# ESP32-P4 register map
Vendor: ESPRESSIF SYSTEMS (SHANGHAI) CO., LTD.; Series: ESP32 P-Series; File version: 3
CPU: RV32IMAFC r0p0, little endian, no MPU, FPU, 0 interrupt priority bits
Address unit: 32 bits
Registers are 32-bit, read-write, reset 0x0 unless marked. A register's access mark holds for its fields unless they carry their own. Offsets are from the block's base; [hi:lo] are bit positions; {n}, {i} and the like mark numbered series; 'fields as' and 'values as' point back to an identical list.

## MEMSPI2 — Memory SPI 2
Base 0x5008E000
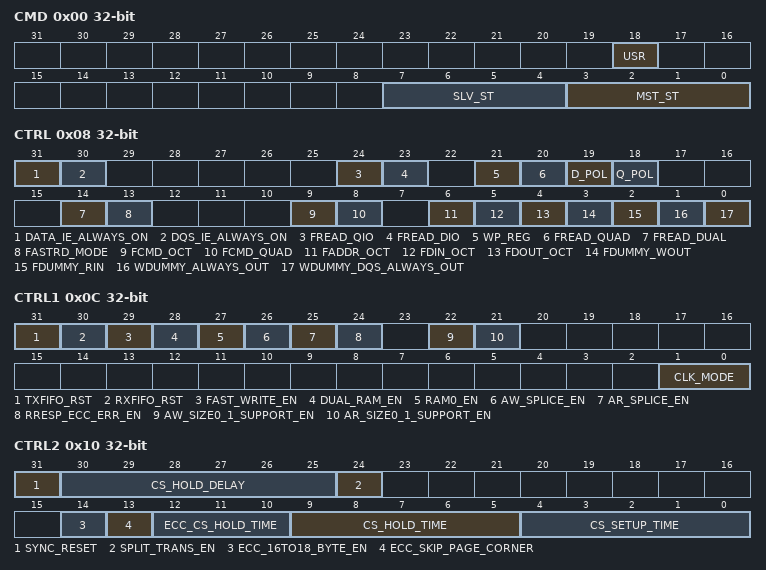
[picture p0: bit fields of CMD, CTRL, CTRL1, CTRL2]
0x00 CMD access per field
  [18] USR rw, [7:4] SLV_ST ro, [3:0] MST_ST ro
0x08 CTRL
  [31] DATA_IE_ALWAYS_ON, [30] DQS_IE_ALWAYS_ON, [24] FREAD_QIO, [23] FREAD_DIO, [21] WP_REG, [20] FREAD_QUAD, [19] D_POL, [18] Q_POL, [14] FREAD_DUAL, [13] FASTRD_MODE, [9] FCMD_OCT, [8] FCMD_QUAD, [6] FADDR_OCT, [5] FDIN_OCT, [4] FDOUT_OCT, [3] FDUMMY_WOUT, [2] FDUMMY_RIN, [1] WDUMMY_ALWAYS_OUT, [0] WDUMMY_DQS_ALWAYS_OUT
0x0C CTRL1 access per field
  [31] TXFIFO_RST wo, [30] RXFIFO_RST wo, [29] FAST_WRITE_EN rw, [28] DUAL_RAM_EN rw, [27] RAM0_EN rw, [26] AW_SPLICE_EN rw, [25] AR_SPLICE_EN rw, [24] RRESP_ECC_ERR_EN rw, [22] AW_SIZE0_1_SUPPORT_EN rw, [21] AR_SIZE0_1_SUPPORT_EN rw, [1:0] CLK_MODE rw
0x10 CTRL2 access per field
  [31] SYNC_RESET wo, [30:25] CS_HOLD_DELAY rw, [24] SPLIT_TRANS_EN rw, [14] ECC_16TO18_BYTE_EN rw, [13] ECC_SKIP_PAGE_CORNER rw, [12:10] ECC_CS_HOLD_TIME rw, [9:5] CS_HOLD_TIME rw, [4:0] CS_SETUP_TIME rw
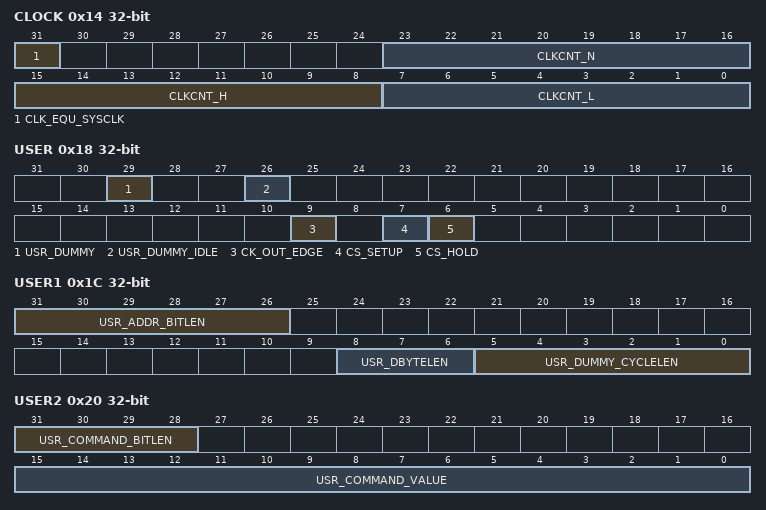
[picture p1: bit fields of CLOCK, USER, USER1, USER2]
0x14 CLOCK
  [31] CLK_EQU_SYSCLK, [23:16] CLKCNT_N, [15:8] CLKCNT_H, [7:0] CLKCNT_L
0x18 USER
  [29] USR_DUMMY, [26] USR_DUMMY_IDLE, [9] CK_OUT_EDGE, [7] CS_SETUP, [6] CS_HOLD
0x1C USER1
  [31:26] USR_ADDR_BITLEN, [8:6] USR_DBYTELEN, [5:0] USR_DUMMY_CYCLELEN
0x20 USER2
  [31:28] USR_COMMAND_BITLEN, [15:0] USR_COMMAND_VALUE
0x2C RD_STATUS
  [23:16] WB_MODE
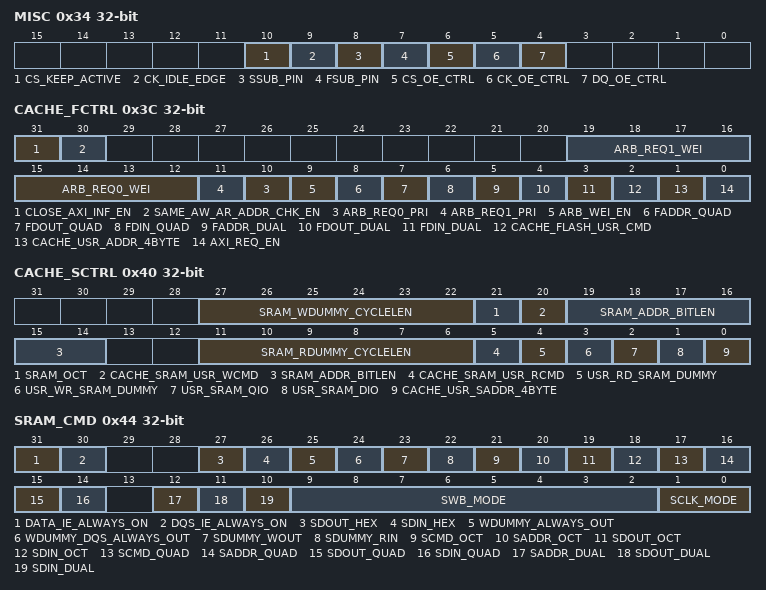
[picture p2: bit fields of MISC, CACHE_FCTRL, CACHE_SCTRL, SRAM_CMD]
0x34 MISC
  [10] CS_KEEP_ACTIVE, [9] CK_IDLE_EDGE, [8] SSUB_PIN, [7] FSUB_PIN, [6] CS_OE_CTRL, [5] CK_OE_CTRL, [4] DQ_OE_CTRL
0x3C CACHE_FCTRL
  [31] CLOSE_AXI_INF_EN, [30] SAME_AW_AR_ADDR_CHK_EN, [4n+15:4n+12] ARB_REQ{n}_WEI (n=0..1), [n+10] ARB_REQ{n}_PRI (n=0..1), [9] ARB_WEI_EN, [8] FADDR_QUAD, [7] FDOUT_QUAD, [6] FDIN_QUAD, [5] FADDR_DUAL, [4] FDOUT_DUAL, [3] FDIN_DUAL, [2] CACHE_FLASH_USR_CMD, [1] CACHE_USR_ADDR_4BYTE, [0] AXI_REQ_EN
0x40 CACHE_SCTRL
  [27:22] SRAM_WDUMMY_CYCLELEN, [21] SRAM_OCT, [20] CACHE_SRAM_USR_WCMD, [19:14] SRAM_ADDR_BITLEN, [11:6] SRAM_RDUMMY_CYCLELEN, [5] CACHE_SRAM_USR_RCMD, [4] USR_RD_SRAM_DUMMY, [3] USR_WR_SRAM_DUMMY, [2] USR_SRAM_QIO, [1] USR_SRAM_DIO, [0] CACHE_USR_SADDR_4BYTE
0x44 SRAM_CMD
  [31] DATA_IE_ALWAYS_ON, [30] DQS_IE_ALWAYS_ON, [27] SDOUT_HEX, [26] SDIN_HEX, [25] WDUMMY_ALWAYS_OUT, [24] WDUMMY_DQS_ALWAYS_OUT, [23] SDUMMY_WOUT, [22] SDUMMY_RIN, [21] SCMD_OCT, [20] SADDR_OCT, [19] SDOUT_OCT, [18] SDIN_OCT, [17] SCMD_QUAD, [16] SADDR_QUAD, [15] SDOUT_QUAD, [14] SDIN_QUAD, [12] SADDR_DUAL, [11] SDOUT_DUAL, [10] SDIN_DUAL, [9:2] SWB_MODE, [1:0] SCLK_MODE
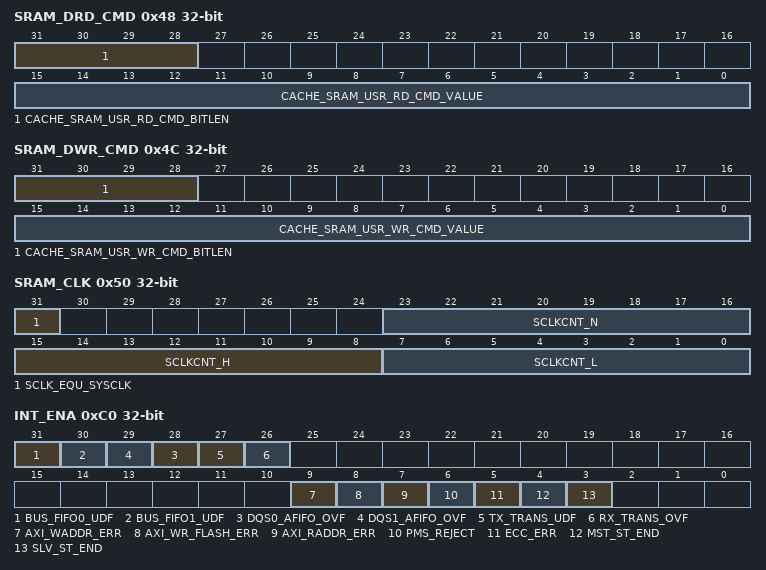
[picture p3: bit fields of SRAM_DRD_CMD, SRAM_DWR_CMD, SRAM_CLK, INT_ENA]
0x48 SRAM_DRD_CMD
  [31:28] CACHE_SRAM_USR_RD_CMD_BITLEN, [15:0] CACHE_SRAM_USR_RD_CMD_VALUE
0x4C SRAM_DWR_CMD
  [31:28] CACHE_SRAM_USR_WR_CMD_BITLEN, [15:0] CACHE_SRAM_USR_WR_CMD_VALUE
0x50 SRAM_CLK
  [31] SCLK_EQU_SYSCLK, [23:16] SCLKCNT_N, [15:8] SCLKCNT_H, [7:0] SCLKCNT_L
0x54 FSM
  [18:7] LOCK_DELAY_TIME
0xC0 INT_ENA
  [31] BUS_FIFO0_UDF, [30] BUS_FIFO1_UDF, [n+28] DQS{n}_AFIFO_OVF (n=0..1), [27] TX_TRANS_UDF, [26] RX_TRANS_OVF, [9] AXI_WADDR_ERR, [8] AXI_WR_FLASH_ERR, [7] AXI_RADDR_ERR, [6] PMS_REJECT, [5] ECC_ERR, [4] MST_ST_END, [3] SLV_ST_END
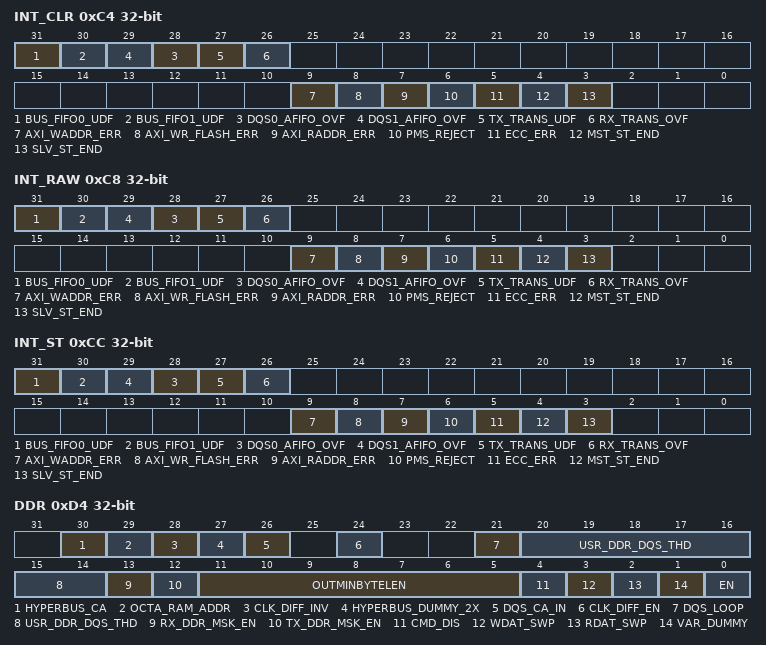
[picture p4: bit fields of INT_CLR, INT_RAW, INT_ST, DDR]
0xC4 INT_CLR wo
  [31] BUS_FIFO0_UDF write-1-clears, [30] BUS_FIFO1_UDF write-1-clears, [n+28] DQS{n}_AFIFO_OVF (n=0..1) write-1-clears, [27] TX_TRANS_UDF write-1-clears, [26] RX_TRANS_OVF write-1-clears, [9] AXI_WADDR_ERR write-1-clears, [8] AXI_WR_FLASH_ERR write-1-clears, [7] AXI_RADDR_ERR write-1-clears, [6] PMS_REJECT write-1-clears, [5] ECC_ERR write-1-clears, [4] MST_ST_END write-1-clears, [3] SLV_ST_END write-1-clears
0xC8 INT_RAW
  fields as INT_ENA
0xCC INT_ST ro
  fields as INT_ENA
0xD4 DDR
  [30] HYPERBUS_CA, [29] OCTA_RAM_ADDR, [28] CLK_DIFF_INV, [27] HYPERBUS_DUMMY_2X, [26] DQS_CA_IN, [24] CLK_DIFF_EN, [21] DQS_LOOP, [20:14] USR_DDR_DQS_THD, [13] RX_DDR_MSK_EN, [12] TX_DDR_MSK_EN, [11:5] OUTMINBYTELEN, [4] CMD_DIS, [3] WDAT_SWP, [2] RDAT_SWP, [1] VAR_DUMMY, [0] EN
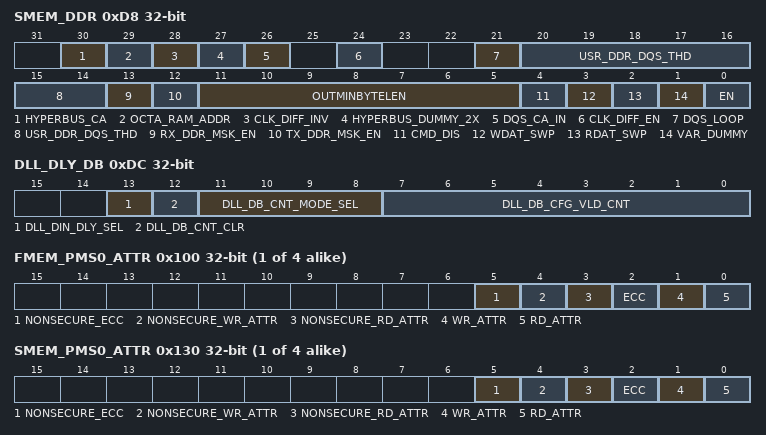
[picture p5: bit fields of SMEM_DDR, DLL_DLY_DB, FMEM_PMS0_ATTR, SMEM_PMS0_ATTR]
0xD8 SMEM_DDR
  fields as DDR
0xDC DLL_DLY_DB
  [13] DLL_DIN_DLY_SEL, [12] DLL_DB_CNT_CLR, [11:8] DLL_DB_CNT_MODE_SEL, [7:0] DLL_DB_CFG_VLD_CNT
0xE0 DLL_DB_ST0 ro
  [31:0] DB_FIFO_CNT_H
0xE4 DLL_DB_ST1 ro
  [31:0] DB_FIFO_CNT_L
{0x100+4i} FMEM_PMS{i}_ATTR (i=0..3)
  [5] NONSECURE_ECC, [4] NONSECURE_WR_ATTR, [3] NONSECURE_RD_ATTR, [2] ECC, [1] WR_ATTR, [0] RD_ATTR
{0x110+4i} FMEM_PMS{i}_ADDR (i=0..3)
  [26:0] ADDR_S
{0x120+4i} FMEM_PMS{i}_SIZE (i=0..3)
  [14:0] SIZE
{0x130+4i} SMEM_PMS{i}_ATTR (i=0..3)
  fields as FMEM_PMS0_ATTR
{0x140+4i} SMEM_PMS{i}_ADDR (i=0..3)
  [26:0] ADDR_S
{0x150+4i} SMEM_PMS{i}_SIZE (i=0..3)
  [14:0] SIZE
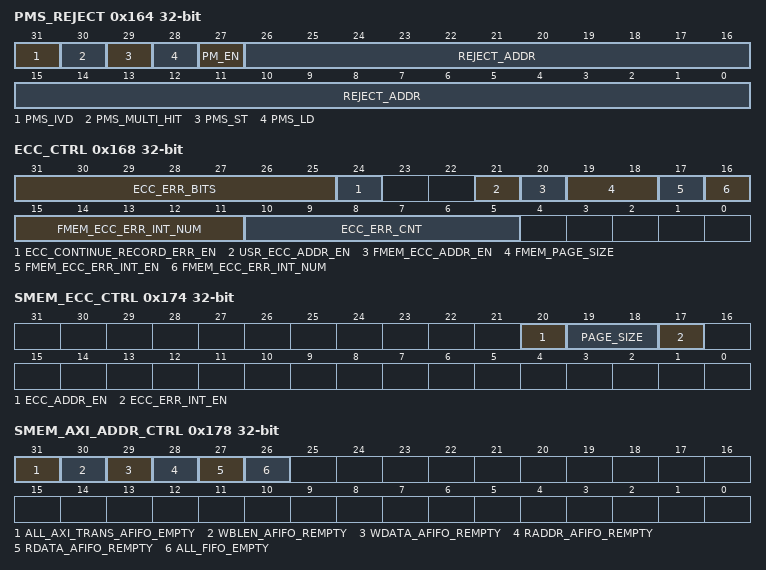
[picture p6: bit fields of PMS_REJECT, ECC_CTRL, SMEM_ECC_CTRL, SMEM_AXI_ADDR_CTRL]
0x164 PMS_REJECT
  [31] PMS_IVD, [30] PMS_MULTI_HIT, [29] PMS_ST, [28] PMS_LD, [27] PM_EN, [26:0] REJECT_ADDR
0x168 ECC_CTRL
  [31:25] ECC_ERR_BITS, [24] ECC_CONTINUE_RECORD_ERR_EN, [21] USR_ECC_ADDR_EN, [20] FMEM_ECC_ADDR_EN, [19:18] FMEM_PAGE_SIZE, [17] FMEM_ECC_ERR_INT_EN, [16:11] FMEM_ECC_ERR_INT_NUM, [10:5] ECC_ERR_CNT
0x16C ECC_ERR_ADDR
  [26:0] ECC_ERR_ADDR
0x170 AXI_ERR_ADDR
  [26:0] AXI_ERR_ADDR
0x174 SMEM_ECC_CTRL
  [20] ECC_ADDR_EN, [19:18] PAGE_SIZE, [17] ECC_ERR_INT_EN
0x178 SMEM_AXI_ADDR_CTRL ro
  [31] ALL_AXI_TRANS_AFIFO_EMPTY, [30] WBLEN_AFIFO_REMPTY, [29] WDATA_AFIFO_REMPTY, [28] RADDR_AFIFO_REMPTY, [27] RDATA_AFIFO_REMPTY, [26] ALL_FIFO_EMPTY
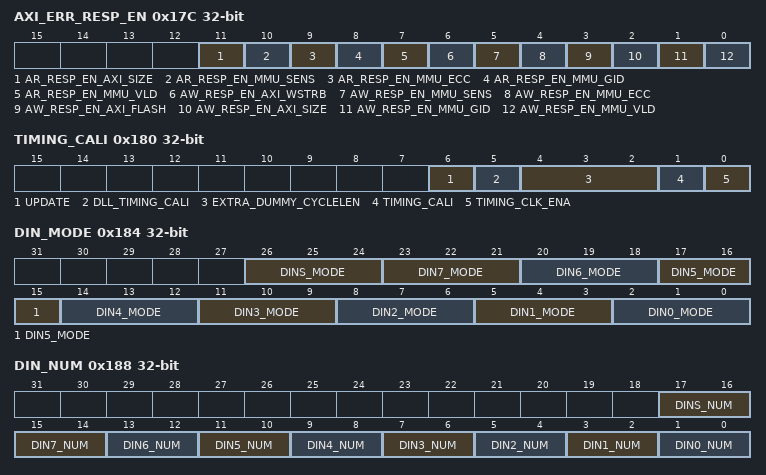
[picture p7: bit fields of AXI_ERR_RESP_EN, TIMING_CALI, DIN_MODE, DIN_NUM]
0x17C AXI_ERR_RESP_EN
  [11] AR_RESP_EN_AXI_SIZE, [10] AR_RESP_EN_MMU_SENS, [9] AR_RESP_EN_MMU_ECC, [8] AR_RESP_EN_MMU_GID, [7] AR_RESP_EN_MMU_VLD, [6] AW_RESP_EN_AXI_WSTRB, [5] AW_RESP_EN_MMU_SENS, [4] AW_RESP_EN_MMU_ECC, [3] AW_RESP_EN_AXI_FLASH, [2] AW_RESP_EN_AXI_SIZE, [1] AW_RESP_EN_MMU_GID, [0] AW_RESP_EN_MMU_VLD
0x180 TIMING_CALI access per field
  [6] UPDATE wo, [5] DLL_TIMING_CALI rw, [4:2] EXTRA_DUMMY_CYCLELEN rw, [1] TIMING_CALI rw, [0] TIMING_CLK_ENA rw
0x184 DIN_MODE
  [26:24] DINS_MODE, [3n+2:3n] DIN{n}_MODE (n=0..7)
0x188 DIN_NUM
  [17:16] DINS_NUM, [2n+1:2n] DIN{n}_NUM (n=0..7)
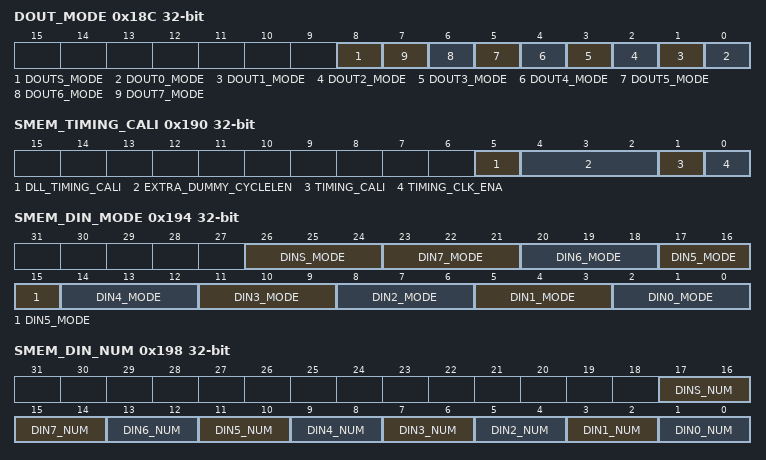
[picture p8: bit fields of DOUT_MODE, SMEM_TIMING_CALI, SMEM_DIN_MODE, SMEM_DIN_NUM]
0x18C DOUT_MODE
  [8] DOUTS_MODE, [n] DOUT{n}_MODE (n=0..7)
0x190 SMEM_TIMING_CALI
  [5] DLL_TIMING_CALI, [4:2] EXTRA_DUMMY_CYCLELEN, [1] TIMING_CALI, [0] TIMING_CLK_ENA
0x194 SMEM_DIN_MODE
  [26:24] DINS_MODE, [3n+2:3n] DIN{n}_MODE (n=0..7)
0x198 SMEM_DIN_NUM
  [17:16] DINS_NUM, [2n+1:2n] DIN{n}_NUM (n=0..7)
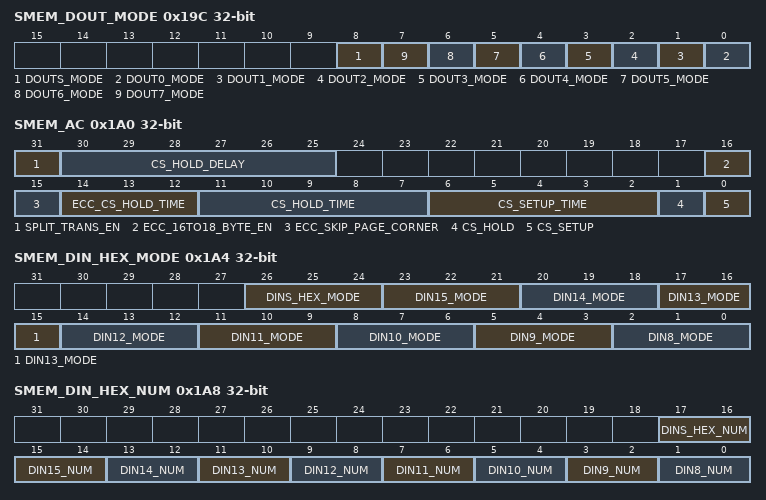
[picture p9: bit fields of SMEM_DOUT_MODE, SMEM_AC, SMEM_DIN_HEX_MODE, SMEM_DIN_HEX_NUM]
0x19C SMEM_DOUT_MODE
  [8] DOUTS_MODE, [n] DOUT{n}_MODE (n=0..7)
0x1A0 SMEM_AC
  [31] SPLIT_TRANS_EN, [30:25] CS_HOLD_DELAY, [16] ECC_16TO18_BYTE_EN, [15] ECC_SKIP_PAGE_CORNER, [14:12] ECC_CS_HOLD_TIME, [11:7] CS_HOLD_TIME, [6:2] CS_SETUP_TIME, [1] CS_HOLD, [0] CS_SETUP
0x1A4 SMEM_DIN_HEX_MODE
  [26:24] DINS_HEX_MODE, [3n-22:3n-24] DIN{n}_MODE (n=8..15)
0x1A8 SMEM_DIN_HEX_NUM
  [17:16] DINS_HEX_NUM, [2n-15:2n-16] DIN{n}_NUM (n=8..15)
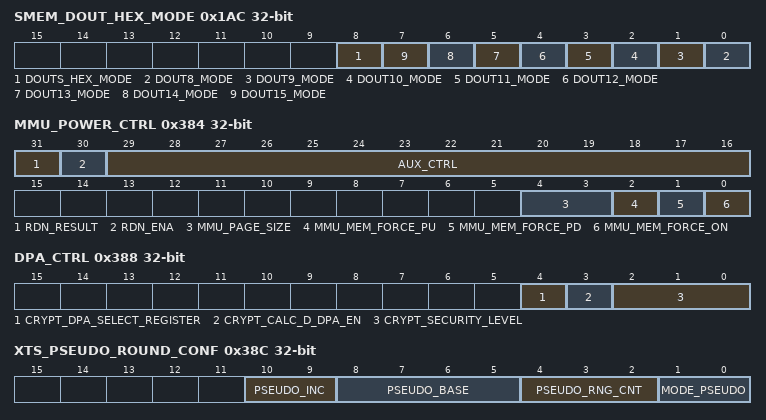
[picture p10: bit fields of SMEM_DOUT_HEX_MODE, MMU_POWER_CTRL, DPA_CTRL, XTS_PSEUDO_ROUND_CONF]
0x1AC SMEM_DOUT_HEX_MODE
  [8] DOUTS_HEX_MODE, [n-8] DOUT{n}_MODE (n=8..15)
0x200 CLOCK_GATE
  [0] CLK_EN
0x300 XTS_PLAIN_BASE
  [31:0] XTS_PLAIN
0x340 XTS_LINESIZE
  [1:0] XTS_LINESIZE
0x344 XTS_DESTINATION
  [0] XTS_DESTINATION
0x348 XTS_PHYSICAL_ADDRESS
  [29:0] XTS_PHYSICAL_ADDRESS
0x34C XTS_TRIGGER wo
  [0] XTS_TRIGGER
0x350 XTS_RELEASE wo
  [0] XTS_RELEASE
0x354 XTS_DESTROY wo
  [0] XTS_DESTROY
0x358 XTS_STATE ro
  [1:0] XTS_STATE
0x35C XTS_DATE
  [29:0] XTS_DATE
0x37C MMU_ITEM_CONTENT
  [13] SENSITIVE — Decrypt via flash encryption when set (flash MMU)
  [12] VALID — Entry is valid when set (flash MMU)
  [12] SPIRAM_SENSITIVE — Decrypt via cache encryption when set (SPIRAM MMU)
  [11] SPIRAM_VALID — Entry is valid when set (SPIRAM MMU)
  [10] ACCESS_SPIRAM — Map to SPIRAM/PSRAM when set (flash when clear)
  [9:0] PADDR — Physical page number
0x380 MMU_ITEM_INDEX
0x384 MMU_POWER_CTRL access per field
  [31] RDN_RESULT ro, [30] RDN_ENA rw, [29:16] AUX_CTRL rw, [4:3] MMU_PAGE_SIZE rw, [2] MMU_MEM_FORCE_PU rw, [1] MMU_MEM_FORCE_PD rw, [0] MMU_MEM_FORCE_ON rw
0x388 DPA_CTRL
  [4] CRYPT_DPA_SELECT_REGISTER, [3] CRYPT_CALC_D_DPA_EN, [2:0] CRYPT_SECURITY_LEVEL
0x38C XTS_PSEUDO_ROUND_CONF
  [10:9] PSEUDO_INC, [8:5] PSEUDO_BASE, [4:2] PSEUDO_RNG_CNT, [1:0] MODE_PSEUDO
0x3F0 REGISTERRND_ECO_HIGH
0x3F4 REGISTERRND_ECO_LOW
0x3FC DATE
  [27:0] DATE
